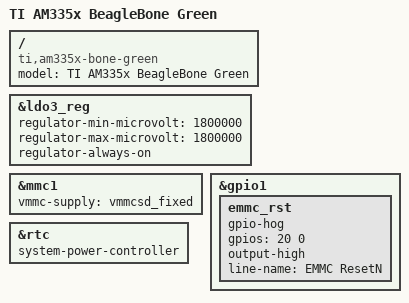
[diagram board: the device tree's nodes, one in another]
/*
 * Copyright (C) 2012 Texas Instruments Incorporated - http://www.ti.com/
 *
 * This program is free software; you can redistribute it and/or modify
 * it under the terms of the GNU General Public License version 2 as
 * published by the Free Software Foundation.
 */
/dts-v1/;

#include "am33xx.dtsi"
#include "am335x-bone-common.dtsi"
#include "am33xx-overlay-edma-fix.dtsi"

/ {
	model = "TI AM335x BeagleBone Green";
	compatible = "ti,am335x-bone-green", "ti,am335x-bone-black", "ti,am335x-bone", "ti,am33xx";
};

&ldo3_reg {
	regulator-min-microvolt = <1800000>;
	regulator-max-microvolt = <1800000>;
	regulator-always-on;
};

&mmc1 {
	vmmc-supply = <&vmmcsd_fixed>;
};

/* EMMC in reset */
&gpio1 {
	emmc_rst {
		gpio-hog;
		gpios = <20 0>;
		output-high;
		line-name = "EMMC ResetN";
	};
};

&rtc {
	system-power-controller;
};
